AUTOSAR XML (schema 4-0-3)
standard types defined: Boolean, UInt16
package /AUTOSAR_Platform/DataConstrs
  range DC_Boolean: raw 0..1
  range DC_UInt16: raw 0..65535
package /PATAC/MSM/ComponentTypes
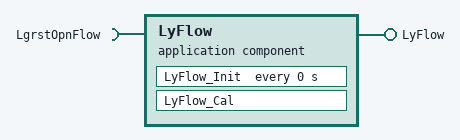
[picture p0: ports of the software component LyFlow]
  application sw component type LyFlow
    provide port LyFlow: server-com-spec{operation=LyFlow/Cal, queue-length=1}, provided-interface=LyFlow
    require port LgrstOpnFlow: client-com-spec=LgrstOpnFlow/Cal, required-interface=LgrstOpnFlow
    behavior LyFlow_InternalBehavior
      operation invoked event OIT_LyFlow_Cal_LyFlow_Cal: start-on-event=LyFlow_Cal, operation=LyFlow.Cal
      timing event LyFlow_InitEvent: start-on-event=LyFlow_Init, period=0
      runnable LyFlow_Cal
        sync call SC_LgrstOpnFlow_Cal: operation=LgrstOpnFlow.Cal, timeout=0
      runnable LyFlow_Init
  swc implementation LyFlow_Implementation: behavior=LyFlow_InternalBehavior
    code-descriptors:
      code Default: artifact-descriptors=autosar-engineering-object={short-label=Default, category=SWSRC}
package /PATAC/MSM/ModeAdjust/PortInterface
  client server interface LgrstOpnFlow
    operation Cal
      9 x arg, all with server-argument-impl-policy=USE-ARGUMENT-TYPE:
        LgrstUpwdDnwdPos: type=UInt16, direction=IN
        LgrstUpwdDnwdOpenPos1: type=UInt16, direction=IN
        LgrstUpwdStgDone: type=Boolean, direction=IN
        FtrstStgDone: type=Boolean, direction=IN
        LgrstInwdStgDone: type=Boolean, direction=IN
        Failflg: type=Boolean, direction=OUT
        LgrstInwdOtwdEn: type=Boolean, direction=OUT
        LgrstUpwdDnwdEn: type=Boolean, direction=OUT
        FtrstEn: type=Boolean, direction=OUT
  client server interface LyFlow
    operation Cal
      20 x arg, all with server-argument-impl-policy=USE-ARGUMENT-TYPE:
        BkReclnStgDone: type=Boolean, direction=IN
        LgrstUpwdDnwdPos: type=UInt16, direction=IN
        LgrstUpwdDnwdOpenPos1: type=UInt16, direction=IN
        LgrstUpwdStgDone: type=Boolean, direction=IN
        FtrstStgDone: type=Boolean, direction=IN
        LgrstInwdStgDone: type=Boolean, direction=IN
        Chkhdflg: type=Boolean, direction=IN
        HdrstUpwdDnwdStgDone: type=Boolean, direction=IN
        HdrstFrwdBkwdStgDone: type=Boolean, direction=IN
        FwdBkwdStgDone: type=Boolean, direction=IN
        FwdBkwdIsPosAlready: type=Boolean, direction=IN
        Failflg: type=Boolean, direction=OUT
        BkReclnEn: type=Boolean, direction=OUT
        HdrstUpwdEn: type=Boolean, direction=OUT
        HdrstFrwdEn: type=Boolean, direction=OUT
        LgrstUpwdDnwdEn: type=Boolean, direction=OUT
        FtrstEn: type=Boolean, direction=OUT
        LgrstInwdOtwdEn: type=Boolean, direction=OUT
        FwdBkwdEn: type=Boolean, direction=OUT
        FailBkwd: type=Boolean, direction=OUT
